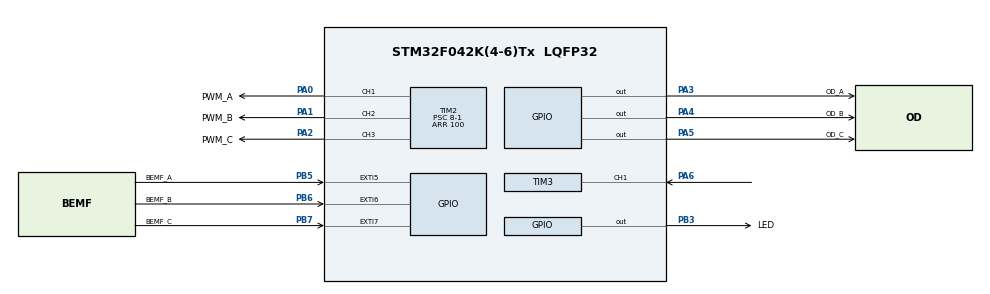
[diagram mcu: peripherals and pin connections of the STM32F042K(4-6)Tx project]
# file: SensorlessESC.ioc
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Mcu.Family=STM32F0
Mcu.Name=STM32F042K(4-6)Tx
Mcu.Package=LQFP32
NVIC.EXTI4_15_IRQn=true\:2\:0\:true\:false\:true\:true\:true
NVIC.TIM2_IRQn=true\:1\:0\:true\:false\:true\:true\:true
NVIC.TIM3_IRQn=true\:0\:0\:false\:false\:true\:true\:true
PA0.GPIO_Label=PWM_A
PA0.Signal=S_TIM2_CH1_ETR
PA1.GPIO_Label=PWM_B
PA1.Signal=S_TIM2_CH2
PA2.GPIO_Label=PWM_C
PA2.Signal=S_TIM2_CH3
PA3.GPIO_Label=OD_A
PA3.Signal=GPIO_Output
PA4.GPIO_Label=OD_B
PA4.Signal=GPIO_Output
PA5.GPIO_Label=OD_C
PA5.Signal=GPIO_Output
PA6.Signal=S_TIM3_CH1
PB3.GPIO_Label=LED
PB3.Signal=GPIO_Output
PB5.GPIO_Label=BEMF_A
PB5.GPIO_ModeDefaultEXTI=GPIO_MODE_IT_FALLING
PB5.Signal=GPXTI5
PB6.GPIO_Label=BEMF_B
PB6.GPIO_ModeDefaultEXTI=GPIO_MODE_IT_RISING_FALLING
PB6.Signal=GPXTI6
PB7.GPIO_Label=BEMF_C
PB7.GPIO_ModeDefaultEXTI=GPIO_MODE_IT_RISING_FALLING
PB7.Signal=GPXTI7
ProjectManager.HeapSize=0x200
ProjectManager.StackSize=0x400
ProjectManager.TargetToolchain=STM32CubeIDE
SH.S_TIM2_CH1_ETR.0=TIM2_CH1,PWM Generation1 CH1
SH.S_TIM2_CH2.0=TIM2_CH2,PWM Generation2 CH2
SH.S_TIM2_CH3.0=TIM2_CH3,PWM Generation3 CH3
SH.S_TIM3_CH1.0=TIM3_CH1,PWM_Input_1
TIM2.Channel-PWM\ Generation1\ CH1=TIM_CHANNEL_1
TIM2.Channel-PWM\ Generation2\ CH2=TIM_CHANNEL_2
TIM2.Channel-PWM\ Generation3\ CH3=TIM_CHANNEL_3
TIM2.Period=100
TIM2.Prescaler=8-1
board=custom

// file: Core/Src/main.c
/* USER CODE BEGIN Header */
/**
  ******************************************************************************
  * @file           : main.c
  * @brief          : Main program body
  ******************************************************************************
  * @attention
  *
  * <h2><center>&copy; Copyright (c) 2021 STMicroelectronics.
  * All rights reserved.</center></h2>
  *
  * This software component is licensed by ST under BSD 3-Clause license,
  * the "License"; You may not use this file except in compliance with the
  * License. You may obtain a copy of the License at:
  *                        opensource.org/licenses/BSD-3-Clause
  *
  ******************************************************************************
  */
/* USER CODE END Header */
#include "main.h"
#include "tim.h"
#include "gpio.h"

/* USER CODE BEGIN Includes */
#include "bldc.h"

/* USER CODE END Includes */

void SystemClock_Config(void);

int main(void)
{

  /* MCU Configuration--------------------------------------------------------*/

  /* Reset of all peripherals, Initializes the Flash interface and the Systick. */
  HAL_Init();

  /* Configure the system clock */
  SystemClock_Config();

  /* Initialize all configured peripherals */
  MX_GPIO_Init();
  MX_TIM2_Init();
  MX_TIM3_Init();
  /* USER CODE BEGIN 2 */
  bldc_init();

  /* USER CODE END 2 */

  /* Infinite loop */
  /* USER CODE BEGIN WHILE */
  while (1)
  {
	  bldc_loop();
    /* USER CODE END WHILE */

  }
}

void SystemClock_Config(void)
{
  RCC_OscInitTypeDef RCC_OscInitStruct = {0};
  RCC_ClkInitTypeDef RCC_ClkInitStruct = {0};

  /** Initializes the RCC Oscillators according to the specified parameters
  * in the RCC_OscInitTypeDef structure.
  */
  RCC_OscInitStruct.OscillatorType = RCC_OSCILLATORTYPE_HSI;
  RCC_OscInitStruct.HSIState = RCC_HSI_ON;
  RCC_OscInitStruct.HSICalibrationValue = RCC_HSICALIBRATION_DEFAULT;
  RCC_OscInitStruct.PLL.PLLState = RCC_PLL_NONE;
  if (HAL_RCC_OscConfig(&RCC_OscInitStruct) != HAL_OK)
  {
    Error_Handler();
  }
  /** Initializes the CPU, AHB and APB buses clocks
  */
  RCC_ClkInitStruct.ClockType = RCC_CLOCKTYPE_HCLK|RCC_CLOCKTYPE_SYSCLK
                              |RCC_CLOCKTYPE_PCLK1;
  RCC_ClkInitStruct.SYSCLKSource = RCC_SYSCLKSOURCE_HSI;
  RCC_ClkInitStruct.AHBCLKDivider = RCC_SYSCLK_DIV1;
  RCC_ClkInitStruct.APB1CLKDivider = RCC_HCLK_DIV1;

  if (HAL_RCC_ClockConfig(&RCC_ClkInitStruct, FLASH_LATENCY_0) != HAL_OK)
  {
    Error_Handler();
  }
}

void Error_Handler(void)
{
  __disable_irq();
  while (1)
  {
  }
}

/************************ (C) COPYRIGHT STMicroelectronics *****END OF FILE****/
